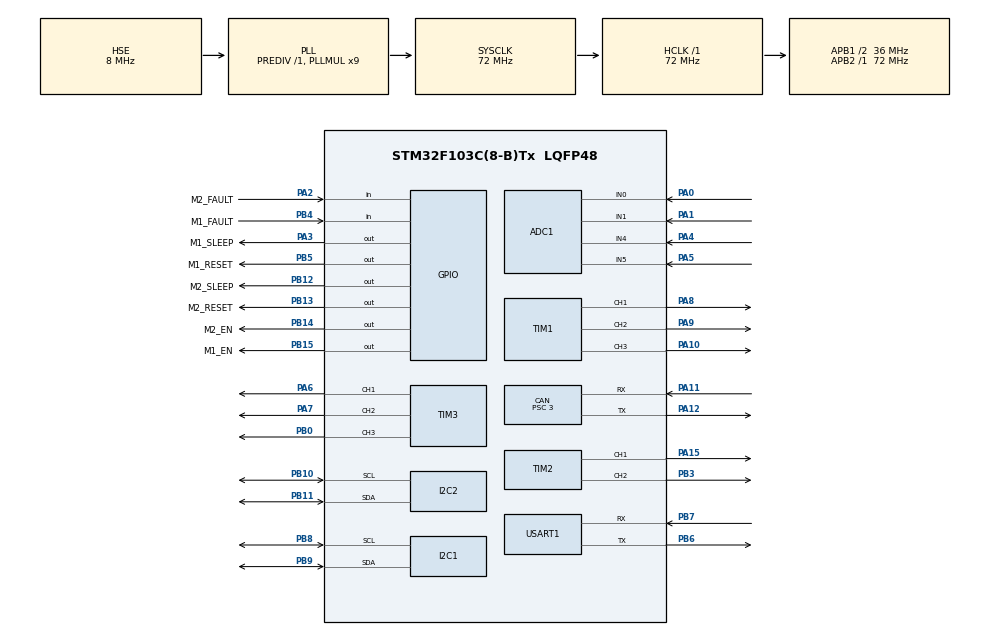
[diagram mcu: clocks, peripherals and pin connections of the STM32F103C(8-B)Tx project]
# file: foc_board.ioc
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ADC1.Channel-1\#ChannelRegularConversion=ADC_CHANNEL_0
ADC1.Channel-2\#ChannelRegularConversion=ADC_CHANNEL_1
ADC1.Channel-3\#ChannelRegularConversion=ADC_CHANNEL_4
ADC1.Channel-4\#ChannelRegularConversion=ADC_CHANNEL_5
ADC1.ContinuousConvMode=ENABLE
ADC1.DiscontinuousConvMode=DISABLE
ADC1.NbrOfConversion=4
ADC1.NbrOfConversionFlag=1
ADC1.Rank-1\#ChannelRegularConversion=1
ADC1.Rank-2\#ChannelRegularConversion=2
ADC1.Rank-3\#ChannelRegularConversion=3
ADC1.Rank-4\#ChannelRegularConversion=4
ADC1.SamplingTime-1\#ChannelRegularConversion=ADC_SAMPLETIME_13CYCLES_5
ADC1.SamplingTime-2\#ChannelRegularConversion=ADC_SAMPLETIME_13CYCLES_5
ADC1.SamplingTime-3\#ChannelRegularConversion=ADC_SAMPLETIME_13CYCLES_5
ADC1.SamplingTime-4\#ChannelRegularConversion=ADC_SAMPLETIME_13CYCLES_5
ADC1.master=1
CAN.BS1=CAN_BS1_5TQ
CAN.BS2=CAN_BS2_6TQ
CAN.CalculateBaudRate=999999
CAN.CalculateTimeBit=1000
CAN.CalculateTimeQuantum=83.33333333333334
CAN.Prescaler=3
CAN.TXFP=ENABLE
Dma.ADC1.0.Direction=DMA_PERIPH_TO_MEMORY
Dma.ADC1.0.Instance=DMA1_Channel1
Dma.ADC1.0.MemDataAlignment=DMA_MDATAALIGN_HALFWORD
Dma.ADC1.0.MemInc=DMA_MINC_ENABLE
Dma.ADC1.0.Mode=DMA_CIRCULAR
Dma.ADC1.0.PeriphDataAlignment=DMA_PDATAALIGN_HALFWORD
Dma.ADC1.0.PeriphInc=DMA_PINC_DISABLE
Dma.ADC1.0.Priority=DMA_PRIORITY_LOW
Dma.Request0=ADC1
FREERTOS.Tasks01=defaultTask,0,128,StartDefaultTask,Default,NULL,Dynamic,NULL,NULL
FREERTOS.configCHECK_FOR_STACK_OVERFLOW=1
Mcu.Family=STM32F1
Mcu.Name=STM32F103C(8-B)Tx
Mcu.Package=LQFP48
NVIC.CAN1_RX1_IRQn=true\:5\:0\:false\:false\:true\:true\:true\:true\:true
NVIC.DMA1_Channel1_IRQn=true\:5\:0\:false\:false\:true\:true\:false\:true\:true
NVIC.PriorityGroup=NVIC_PRIORITYGROUP_4
NVIC.TIM4_IRQn=true\:5\:0\:false\:false\:true\:true\:true\:true\:true
NVIC.USB_LP_CAN1_RX0_IRQn=true\:5\:0\:false\:false\:true\:true\:false\:true\:true
PA0-WKUP.Signal=ADCx_IN0
PA1.Signal=ADCx_IN1
PA10.Signal=S_TIM1_CH3
PA11.Mode=CAN_Activate
PA11.Signal=CAN_RX
PA12.Mode=CAN_Activate
PA12.Signal=CAN_TX
PA13.Mode=Serial_Wire
PA13.Signal=SYS_JTMS-SWDIO
PA14.Mode=Serial_Wire
PA14.Signal=SYS_JTCK-SWCLK
PA15.Signal=S_TIM2_CH1_ETR
PA2.GPIO_Label=M2_FAULT
PA2.Signal=GPIO_Input
PA3.GPIO_Label=M1_SLEEP
PA3.GPIO_PuPd=GPIO_PULLDOWN
PA3.Signal=GPIO_Output
PA4.Signal=ADCx_IN4
PA5.Signal=ADCx_IN5
PA6.Signal=S_TIM3_CH1
PA7.Signal=S_TIM3_CH2
PA8.Signal=S_TIM1_CH1
PA9.Signal=S_TIM1_CH2
PB0.Signal=S_TIM3_CH3
PB10.Mode=I2C
PB10.Signal=I2C2_SCL
PB11.Mode=I2C
PB11.Signal=I2C2_SDA
PB12.GPIO_Label=M2_SLEEP
PB12.GPIO_PuPd=GPIO_PULLDOWN
PB12.Signal=GPIO_Output
PB13.GPIO_Label=M2_RESET
PB13.GPIO_PuPd=GPIO_PULLDOWN
PB13.Signal=GPIO_Output
PB14.GPIO_Label=M2_EN
PB14.GPIO_PuPd=GPIO_PULLDOWN
PB14.Signal=GPIO_Output
PB15.GPIO_Label=M1_EN
PB15.GPIO_PuPd=GPIO_PULLDOWN
PB15.Signal=GPIO_Output
PB3.Signal=S_TIM2_CH2
PB4.GPIO_Label=M1_FAULT
PB4.Signal=GPIO_Input
PB5.GPIO_Label=M1_RESET
PB5.GPIO_PuPd=GPIO_PULLDOWN
PB5.Signal=GPIO_Output
PB6.Mode=Asynchronous
PB6.Signal=USART1_TX
PB7.Mode=Asynchronous
PB7.Signal=USART1_RX
PB8.Mode=I2C
PB8.Signal=I2C1_SCL
PB9.Mode=I2C
PB9.Signal=I2C1_SDA
PD0-OSC_IN.Mode=HSE-External-Oscillator
PD0-OSC_IN.Signal=RCC_OSC_IN
PD1-OSC_OUT.Mode=HSE-External-Oscillator
PD1-OSC_OUT.Signal=RCC_OSC_OUT
ProjectManager.HeapSize=0x400
ProjectManager.StackSize=0x800
ProjectManager.TargetToolchain=MDK-ARM V5.32
RCC.ADCPresc=RCC_ADCPCLK2_DIV6
RCC.AHBFreq_Value=72000000
RCC.APB1CLKDivider=RCC_HCLK_DIV2
RCC.APB1Freq_Value=36000000
RCC.APB1TimFreq_Value=72000000
RCC.APB2Freq_Value=72000000
RCC.APB2TimFreq_Value=72000000
RCC.HCLKFreq_Value=72000000
RCC.PLLMUL=RCC_PLL_MUL9
RCC.PLLSourceVirtual=RCC_PLLSOURCE_HSE
RCC.SYSCLKFreq_VALUE=72000000
RCC.SYSCLKSource=RCC_SYSCLKSOURCE_PLLCLK
RCC.USBFreq_Value=48000000
RCC.USBPrescaler=RCC_USBCLKSOURCE_PLL_DIV1_5
SH.ADCx_IN0.0=ADC1_IN0,IN0
SH.ADCx_IN1.0=ADC1_IN1,IN1
SH.ADCx_IN4.0=ADC1_IN4,IN4
SH.ADCx_IN5.0=ADC1_IN5,IN5
SH.S_TIM1_CH1.0=TIM1_CH1,PWM Generation1 CH1
SH.S_TIM1_CH2.0=TIM1_CH2,PWM Generation2 CH2
SH.S_TIM1_CH3.0=TIM1_CH3,PWM Generation3 CH3
SH.S_TIM2_CH1_ETR.0=TIM2_CH1,PWM Generation1 CH1
SH.S_TIM2_CH2.0=TIM2_CH2,PWM Generation2 CH2
SH.S_TIM3_CH1.0=TIM3_CH1,PWM Generation1 CH1
SH.S_TIM3_CH2.0=TIM3_CH2,PWM Generation2 CH2
SH.S_TIM3_CH3.0=TIM3_CH3,PWM Generation3 CH3
STMicroelectronics.X-CUBE-ALGOBUILD.1.4.0.LibraryCcDSPOoLibraryJjDSPOoLibrary=true
TIM1.Channel-PWM\ Generation1\ CH1=TIM_CHANNEL_1
TIM1.Channel-PWM\ Generation2\ CH2=TIM_CHANNEL_2
TIM1.Channel-PWM\ Generation3\ CH3=TIM_CHANNEL_3
TIM1.CounterMode=TIM_COUNTERMODE_CENTERALIGNED1
TIM1.RepetitionCounter=0
TIM2.Channel-PWM\ Generation1\ CH1=TIM_CHANNEL_1
TIM2.Channel-PWM\ Generation2\ CH2=TIM_CHANNEL_2
TIM3.Channel-PWM\ Generation1\ CH1=TIM_CHANNEL_1
TIM3.Channel-PWM\ Generation2\ CH2=TIM_CHANNEL_2
TIM3.Channel-PWM\ Generation3\ CH3=TIM_CHANNEL_3
TIM3.CounterMode=TIM_COUNTERMODE_CENTERALIGNED1
TIM4.Prescaler=720-1
USART1.VirtualMode=VM_ASYNC
VP_FREERTOS_VS_CMSIS_V1.Mode=CMSIS_V1
VP_STMicroelectronics.X-CUBE-ALGOBUILD_VS_DSPOoLibraryJjLibrary_1.4.0_1.4.0.Mode=DSPOoLibraryJjLibrary
VP_TIM1_VS_ClockSourceINT.Mode=Internal
VP_TIM3_VS_ClockSourceINT.Mode=Internal
VP_TIM4_VS_ClockSourceINT.Mode=Internal
board=custom

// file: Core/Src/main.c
/* USER CODE BEGIN Header */
/**
 ******************************************************************************
 * @file           : main.c
 * @brief          : Main program body
 ******************************************************************************
 * @attention
 *
 * Copyright (c) 2025 STMicroelectronics.
 * All rights reserved.
 *
 * This software is licensed under terms that can be found in the LICENSE file
 * in the root directory of this software component.
 * If no LICENSE file comes with this software, it is provided AS-IS.
 *
 ******************************************************************************
 */
/* USER CODE END Header */
#include "main.h"
#include "cmsis_os.h"
#include "adc.h"
#include "can.h"
#include "dma.h"
#include "i2c.h"
#include "tim.h"
#include "usart.h"
#include "gpio.h"

/* USER CODE BEGIN Includes */
#include "as5600.h"
#include "bsp_can.h"
#include "bsp_i2c.h"
// #include "bsp_time.h"
#include "common.h"
#include "can_rxtx.h"
/* USER CODE END Includes */

void SystemClock_Config(void);
void MX_FREERTOS_Init(void);

int main(void)
{

  /* MCU Configuration--------------------------------------------------------*/

  /* Reset of all peripherals, Initializes the Flash interface and the Systick. */
  HAL_Init();

  /* Configure the system clock */
  SystemClock_Config();

  /* Initialize all configured peripherals */
  MX_GPIO_Init();
  MX_DMA_Init();
  MX_ADC1_Init();
  MX_CAN_Init();
  MX_I2C1_Init();
  MX_I2C2_Init();
  MX_TIM1_Init();
  MX_TIM3_Init();
  MX_USART1_UART_Init();
  MX_TIM2_Init();
  MX_TIM4_Init();
  /* USER CODE BEGIN 2 */
  HAL_TIM_PWM_Start(&htim1, TIM_CHANNEL_1);
  HAL_TIM_PWM_Start(&htim1, TIM_CHANNEL_2);
  HAL_TIM_PWM_Start(&htim1, TIM_CHANNEL_3);
  /* USER CODE END 2 */

  /* Call init function for freertos objects (in cmsis_os2.c) */
  MX_FREERTOS_Init();

  /* Start scheduler */
  osKernelStart();

  /* We should never get here as control is now taken by the scheduler */

  /* Infinite loop */
  while (1) {

  }
}

void SystemClock_Config(void)
{
  RCC_OscInitTypeDef RCC_OscInitStruct = {0};
  RCC_ClkInitTypeDef RCC_ClkInitStruct = {0};
  RCC_PeriphCLKInitTypeDef PeriphClkInit = {0};

  /** Initializes the RCC Oscillators according to the specified parameters
  * in the RCC_OscInitTypeDef structure.
  */
  RCC_OscInitStruct.OscillatorType = RCC_OSCILLATORTYPE_HSE;
  RCC_OscInitStruct.HSEState = RCC_HSE_ON;
  RCC_OscInitStruct.HSEPredivValue = RCC_HSE_PREDIV_DIV1;
  RCC_OscInitStruct.HSIState = RCC_HSI_ON;
  RCC_OscInitStruct.PLL.PLLState = RCC_PLL_ON;
  RCC_OscInitStruct.PLL.PLLSource = RCC_PLLSOURCE_HSE;
  RCC_OscInitStruct.PLL.PLLMUL = RCC_PLL_MUL9;
  if (HAL_RCC_OscConfig(&RCC_OscInitStruct) != HAL_OK)
  {
    Error_Handler();
  }

  /** Initializes the CPU, AHB and APB buses clocks
  */
  RCC_ClkInitStruct.ClockType = RCC_CLOCKTYPE_HCLK|RCC_CLOCKTYPE_SYSCLK
                              |RCC_CLOCKTYPE_PCLK1|RCC_CLOCKTYPE_PCLK2;
  RCC_ClkInitStruct.SYSCLKSource = RCC_SYSCLKSOURCE_PLLCLK;
  RCC_ClkInitStruct.AHBCLKDivider = RCC_SYSCLK_DIV1;
  RCC_ClkInitStruct.APB1CLKDivider = RCC_HCLK_DIV2;
  RCC_ClkInitStruct.APB2CLKDivider = RCC_HCLK_DIV1;

  if (HAL_RCC_ClockConfig(&RCC_ClkInitStruct, FLASH_LATENCY_2) != HAL_OK)
  {
    Error_Handler();
  }
  PeriphClkInit.PeriphClockSelection = RCC_PERIPHCLK_ADC;
  PeriphClkInit.AdcClockSelection = RCC_ADCPCLK2_DIV6;
  if (HAL_RCCEx_PeriphCLKConfig(&PeriphClkInit) != HAL_OK)
  {
    Error_Handler();
  }
}

void Error_Handler(void)
{
  __disable_irq();
  while (1) {
  }
}

#ifdef  USE_FULL_ASSERT
/**
  * @brief  Reports the name of the source file and the source line number
  *         where the assert_param error has occurred.
  * @param  file: pointer to the source file name
  * @param  line: assert_param error line source number
  * @retval None
  */
void assert_failed(uint8_t *file, uint32_t line)
{
  /* USER CODE BEGIN 6 */
  /* User can add his own implementation to report the file name and line
     number, ex: printf("Wrong parameters value: file %s on line %d\r\n", file,
     line) */
  /* USER CODE END 6 */
}
#endif /* USE_FULL_ASSERT */

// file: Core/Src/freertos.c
/* USER CODE BEGIN Header */
/**
  ******************************************************************************
  * File Name          : freertos.c
  * Description        : Code for freertos applications
  ******************************************************************************
  * @attention
  *
  * Copyright (c) 2025 STMicroelectronics.
  * All rights reserved.
  *
  * This software is licensed under terms that can be found in the LICENSE file
  * in the root directory of this software component.
  * If no LICENSE file comes with this software, it is provided AS-IS.
  *
  ******************************************************************************
  */
/* USER CODE END Header */

#include "FreeRTOS.h"
#include "task.h"
#include "main.h"
#include "cmsis_os.h"

/* USER CODE BEGIN Includes */
#include "foc_driver.h"
/* USER CODE END Includes */

osThreadId defaultTaskHandle;

void StartDefaultTask(void const * argument);

void MX_FREERTOS_Init(void); /* (MISRA C 2004 rule 8.1) */

/* GetIdleTaskMemory prototype (linked to static allocation support) */
void vApplicationGetIdleTaskMemory( StaticTask_t **ppxIdleTaskTCBBuffer, StackType_t **ppxIdleTaskStackBuffer, uint32_t *pulIdleTaskStackSize );

/* Hook prototypes */
void vApplicationStackOverflowHook(xTaskHandle xTask, signed char *pcTaskName);

/* USER CODE BEGIN 4 */
__weak void vApplicationStackOverflowHook(xTaskHandle xTask, signed char *pcTaskName)
{
   /* Run time stack overflow checking is performed if
   configCHECK_FOR_STACK_OVERFLOW is defined to 1 or 2. This hook function is
   called if a stack overflow is detected. */
}
/* USER CODE END 4 */

/* USER CODE BEGIN GET_IDLE_TASK_MEMORY */
static StaticTask_t xIdleTaskTCBBuffer;
static StackType_t xIdleStack[configMINIMAL_STACK_SIZE];

void vApplicationGetIdleTaskMemory( StaticTask_t **ppxIdleTaskTCBBuffer, StackType_t **ppxIdleTaskStackBuffer, uint32_t *pulIdleTaskStackSize )
{
  *ppxIdleTaskTCBBuffer = &xIdleTaskTCBBuffer;
  *ppxIdleTaskStackBuffer = &xIdleStack[0];
  *pulIdleTaskStackSize = configMINIMAL_STACK_SIZE;
  /* place for user code */
}
/* USER CODE END GET_IDLE_TASK_MEMORY */

void MX_FREERTOS_Init(void) {

  /* Create the thread(s) */
  /* definition and creation of defaultTask */
  osThreadDef(defaultTask, StartDefaultTask, osPriorityNormal, 0, 128);
  defaultTaskHandle = osThreadCreate(osThread(defaultTask), NULL);

}

void StartDefaultTask(void const * argument)
{
  /* USER CODE BEGIN StartDefaultTask */
  FOC_driver_init();
  /* Infinite loop */
  for(;;)
  {
    FOC_driver_main();
    osDelay(1);
  }
  /* USER CODE END StartDefaultTask */
}
